# SKEAZ1284 register map
File version: 1.6
Registers are 8-bit, read-write, reset 0x0 unless marked. A register's access mark holds for its fields unless they carry their own. Offsets are from the block's base; [hi:lo] are bit positions; 'fields as' and 'values as' point back to an identical list.

## OSC — Oscillator
Base 0x40065000; register names take the prefix OSC_
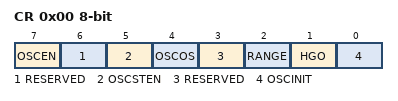
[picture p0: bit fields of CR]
0x00 CR — OSC Control Register
  [7] OSCEN — OSC Enable
    0=OSC module is disabled; 1=OSC module is enabled
  [6] RESERVED ro
  [5] OSCSTEN — OSC Enable in Stop mode
    0=OSC clock is disabled in Stop mode; 1=OSC clock stays enabled in Stop mode
  [4] OSCOS — OSC Output Select
    0=External clock source from EXTAL pin is selected; 1=Oscillator clock source is selected
  [3] RESERVED ro
  [2] RANGE — Frequency Range Select
    0=Low frequency range of 32 kHz; 1=High frequency range of 4-24 MHz
  [1] HGO — High Gain Oscillator Select
    0=Low-power mode; 1=High-gain mode
  [0] OSCINIT ro — OSC Initialization
    0=Oscillator initialization is not complete; 1=Oscillator initialization is completed

## ACMP0 — Analog comparator
Base 0x40073000; register names take the prefix ACMP0_
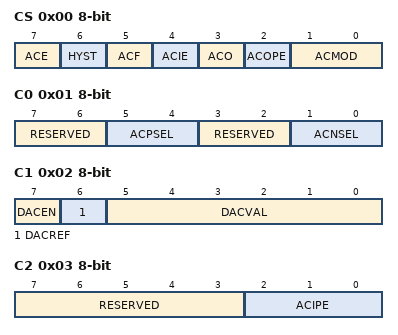
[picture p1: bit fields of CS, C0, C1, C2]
0x00 CS — ACMP Control and Status Register
  [7] ACE — Analog Comparator Enable
    0=The ACMP is disabled; 1=The ACMP is enabled
  [6] HYST — Analog Comparator Hysterisis Selection
    0=20 mV; 1=30 mV
  [5] ACF — ACMP Interrupt Flag Bit
  [4] ACIE — ACMP Interrupt Enable
    0=Disable the ACMP Interrupt; 1=Enable the ACMP Interrupt
  [3] ACO ro — ACMP Output
  [2] ACOPE — ACMP Output Pin Enable
    0=ACMP output cannot be placed onto external pin; 1=ACMP output can be placed onto external pin
  [1:0] ACMOD — ACMP MOD
    0=ACMP interrupt on output falling edge; 1=ACMP interrupt on output rising edge; 2=ACMP interrupt on output falling edge; 3=ACMP interrupt on output falling or rising edge
0x01 C0 — ACMP Control Register 0
  [7:6] RESERVED ro
  [5:4] ACPSEL — ACMP Positive Input Select
    0=External reference 0; 1=External reference 1; 2=External reference 2; 3=DAC output
  [3:2] RESERVED ro
  [1:0] ACNSEL — ACMP Negative Input Select
    values as ACPSEL
0x02 C1 — ACMP Control Register 1
  [7] DACEN — DAC Enable
    0=The DAC is disabled; 1=The DAC is enabled
  [6] DACREF — DAC Reference Select
    0=The DAC selects Bandgap as the reference; 1=The DAC selects VDDA as the reference
  [5:0] DACVAL — DAC Output Level Selection
0x03 C2 — ACMP Control Register 2
  [7:3] RESERVED ro
  [2:0] ACIPE — ACMP Input Pin Enable
    0=The corresponding external analog input is not allowed; 1=The corresponding external analog input is allowed

## ACMP1 — Analog comparator
Base 0x40074000; register names take the prefix ACMP1_
Registers as ACMP0.

## KBI0 — Keyboard interrupts
Base 0x40079000; register names take the prefix KBI0_
0x00 PE 32-bit — KBI Pin Enable Register
  [31:0] KBIPE — KBI Pin Enables
    0=Pin is not enabled as KBI interrupt; 1=Pin is enabled as KBI interrupt
0x04 ES 32-bit — KBI Edge Select Register
  [31:0] KBEDG — KBI Edge Selects
    0=Falling edge/low level; 1=Rising edge/high level
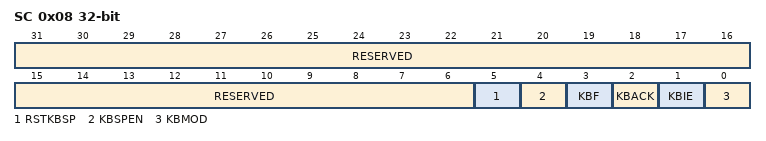
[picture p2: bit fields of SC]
0x08 SC 32-bit — KBI Status and Control Register
  [31:6] RESERVED ro
  [5] RSTKBSP — Reset KBI_SP registe
  [4] KBSPEN — Real KBI_SP register enable
    0=The real time value of Keyboard source pin to be read; 1=The latched value in KBxSP register while interrupt flag occur to be read
  [3] KBF ro — KBI Interrupt Flag
    0=KBI interrupt request not detected; 1=KBI interrupt request detected
  [2] KBACK wo — KBI Acknowledge
  [1] KBIE — KBI Interrupt Enable
    0=KBI interrupt not enabled; 1=KBI interrupt enabled
  [0] KBMOD — KBI Detection Mode
    0=Keyboard detects edges only; 1=Keyboard detects both edges and levels
0x0C SP 32-bit ro — KBI Source Pin Register
  [31:0] SP — KBI Source Pin

## KBI1 — Keyboard interrupts
Base 0x4007A000; register names take the prefix KBI1_
Registers as KBI0.

## PMC — Power management
Base 0x4007D000; register names take the prefix PMC_
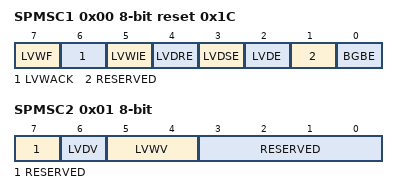
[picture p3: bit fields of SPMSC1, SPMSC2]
0x00 SPMSC1 reset 0x1C — System Power Management Status and Control 1 Register
  [7] LVWF ro — Low-Voltage Warning Flag
    0=Low-voltage warning is not present; 1=Low-voltage warning is present or was present
  [6] LVWACK wo — Low-Voltage Warning Acknowledge
  [5] LVWIE — Low-Voltage Warning Interrupt Enable
    0=Hardware interrupt is disabled (use polling); 1=Requests a hardware interrupt when LVWF = 1
  [4] LVDRE — Low-Voltage Detect Reset Enable
    0=LVD events do not generate hardware resets; 1=Forces an MCU reset when an enabled low-voltage detect event occurs
  [3] LVDSE — Low-Voltage Detect Stop Enable
    0=Low-voltage detect is disabled during Stop mode; 1=Low-voltage detect is enabled during Stop mode
  [2] LVDE — Low-Voltage Detect Enable
    0=LVD logic is disabled; 1=LVD logic is enabled
  [1] RESERVED wo
  [0] BGBE — Bandgap Buffer Enable
    0=Bandgap buffer is disabled; 1=Bandgap buffer is enabled
0x01 SPMSC2 — System Power Management Status and Control 2 Register
  [7] RESERVED ro
  [6] LVDV — Low-Voltage Detect Voltage Select
    0=Low trip point is selected (VLVD = VLVDL); 1=High trip point is selected (VLVD = VLVDH)
  [5:4] LVWV — Low-Voltage Warning Voltage Select
    0=Low trip point is selected (VLVW = VLVW1); 1=Middle 1 trip point is selected (VLVW = VLVW2); 2=Middle 2 trip point is selected (VLVW = VLVW3); 3=High trip point is selected (VLVW = VLVW4)
  [3:0] RESERVED ro
